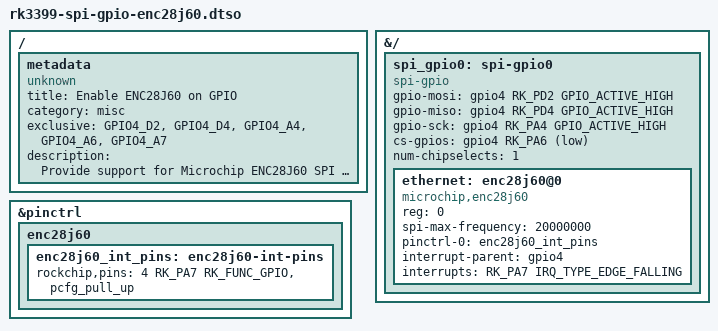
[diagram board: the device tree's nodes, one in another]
/dts-v1/;
/plugin/;

#include <dt-bindings/gpio/gpio.h>
#include <dt-bindings/pinctrl/rockchip.h>
#include <dt-bindings/interrupt-controller/irq.h>

/ {
	metadata {
		title = "Enable ENC28J60 on GPIO";
		compatible = "unknown";
		category = "misc";
		exclusive = "GPIO4_D2", "GPIO4_D4", "GPIO4_A4", "GPIO4_A6", "GPIO4_A7";
		description = "Provide support for Microchip ENC28J60 SPI Ethernet controller on GPIO pins.
Pin definition:
MOSI=16 MISO=18 SCK=36 CS=38 INT=40";
	};
};

&{/} {
	spi_gpio0: spi-gpio0 {
		compatible = "spi-gpio";
		#address-cells = <1>;
		#size-cells = <0>;
		gpio-mosi = <&gpio4 RK_PD2 GPIO_ACTIVE_HIGH>;
		gpio-miso = <&gpio4 RK_PD4 GPIO_ACTIVE_HIGH>;
		gpio-sck = <&gpio4 RK_PA4 GPIO_ACTIVE_HIGH>;
		cs-gpios = <&gpio4 RK_PA6 GPIO_ACTIVE_LOW>;
		num-chipselects = <1>;
		status = "okay";

		ethernet: enc28j60@0 {
			compatible = "microchip,enc28j60";
			reg = <0>;
			spi-max-frequency = <20000000>;

			pinctrl-names = "default";
			pinctrl-0 = <&enc28j60_int_pins>;

			interrupt-parent = <&gpio4>;
			interrupts = <RK_PA7 IRQ_TYPE_EDGE_FALLING>;
		};
	};
};

&pinctrl {
	enc28j60 {
		enc28j60_int_pins: enc28j60-int-pins {
			rockchip,pins = <4 RK_PA7 RK_FUNC_GPIO &pcfg_pull_up>;
		};
	};
};
